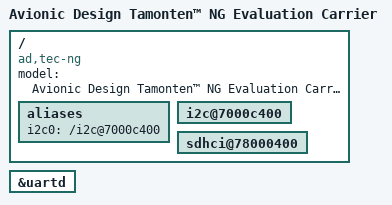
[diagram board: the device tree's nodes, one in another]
/dts-v1/;

#include "tegra30-tamonten.dtsi"

/ {
	model = "Avionic Design Tamonten™ NG Evaluation Carrier";
	compatible = "ad,tec-ng", "nvidia,tegra30";

	aliases {
		i2c0 = "/i2c@7000c400";
	};

	/* GEN2 */
	i2c@7000c400 {
		status = "okay";
	};

	/* SD card slot */
	sdhci@78000400 {
		status = "okay";
	};
};

&uartd {
	status = "okay";
};
